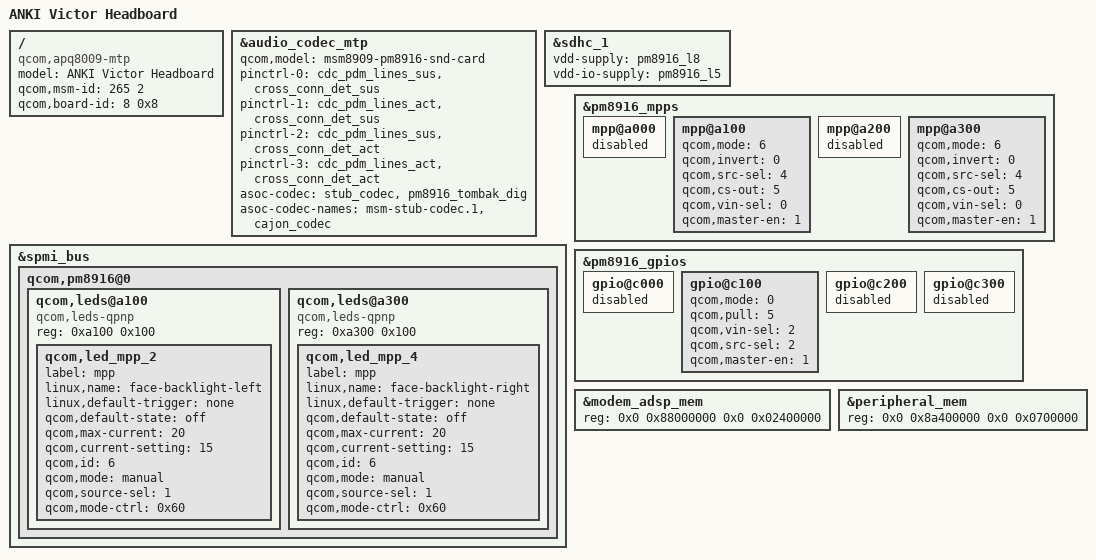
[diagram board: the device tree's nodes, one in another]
/*
 * Copyright (c) 2016, The Linux Foundation. All rights reserved.
 *
 * This program is free software; you can redistribute it and/or modify
 * it under the terms of the GNU General Public License version 2 and
 * only version 2 as published by the Free Software Foundation.
 *
 * This program is distributed in the hope that it will be useful,
 * but WITHOUT ANY WARRANTY; without even the implied warranty of
 * MERCHANTABILITY or FITNESS FOR A PARTICULAR PURPOSE.  See the
 * GNU General Public License for more details.
 */

/dts-v1/;

#include "anki-mtp.dtsi"
#include "msm8909-pm8916.dtsi"
#include "msm8909-pm8916-camera.dtsi"

/ {
	model = "ANKI Victor Headboard";
	compatible = "qcom,apq8009-mtp", "qcom,apq8009", "qcom,mtp";
	qcom,msm-id = <265 2>;
	qcom,board-id= <8 0x8>;   // XXX - this should be our own, right?
};

// The below comes from msm8909-pm8916-mtp - removing disabled hardware

&audio_codec_mtp {
        qcom,model = "msm8909-pm8916-snd-card";
        pinctrl-names =
                "all_off",
                "pri_i2s_act",
                "us_eu_gpio_act",
                "pri_i2s_us_eu_gpio_act";
        pinctrl-0 = <&cdc_pdm_lines_sus &cross_conn_det_sus>;
        pinctrl-1 = <&cdc_pdm_lines_act &cross_conn_det_sus>;
        pinctrl-2 = <&cdc_pdm_lines_sus &cross_conn_det_act>;
        pinctrl-3 = <&cdc_pdm_lines_act &cross_conn_det_act>;
        asoc-codec = <&stub_codec>, <&pm8916_tombak_dig>;
        asoc-codec-names = "msm-stub-codec.1", "cajon_codec";
};

&sdhc_1 {
	vdd-supply = <&pm8916_l8>;
	vdd-io-supply = <&pm8916_l5>;
};

&spmi_bus {
	qcom,pm8916@0 {
		qcom,leds@a100 {
			compatible = "qcom,leds-qpnp";
			reg = <0xa100 0x100>;
			status = "okay";
			qcom,led_mpp_2 {
				label = "mpp";
				linux,name = "face-backlight-left";
				linux,default-trigger = "none";
				qcom,default-state = "off";
				qcom,max-current = <20>;
				qcom,current-setting = <15>;
				qcom,id = <6>;
				qcom,mode = "manual";
				qcom,source-sel = <1>;
				qcom,mode-ctrl = <0x60>;
			};
		};

		qcom,leds@a300 {
			compatible = "qcom,leds-qpnp";
			reg = <0xa300 0x100>;
			status = "okay";
			qcom,led_mpp_4 {
				label = "mpp";
				linux,name = "face-backlight-right";
				linux,default-trigger = "none";
				qcom,default-state = "off";
				qcom,max-current = <20>;
				qcom,current-setting = <15>;
				qcom,id = <6>;
				qcom,mode = "manual";
				qcom,source-sel = <1>;
				qcom,mode-ctrl = <0x60>;
			};
		};
	};
};

&pm8916_mpps {
	mpp@a000 { /* MPP 1 */
		/* VDD_PX */
		status = "disabled";
	};

	mpp@a100 { /* MPP 2 */
		 qcom,mode = <6>;    /* Current sink*/
		 qcom,invert = <0>;    /* Disable invert */
		 qcom,src-sel = <4>;    /* DTEST1 */
		 qcom,cs-out =<5>;
		 qcom,vin-sel = <0>;		/* VPH_PWR */
		 qcom,master-en = <1>;    /* Enable MPP */
	};

	mpp@a200 { /* MPP 3 */
		/* VREF DAC */
		status = "disabled";
	};

	mpp@a300 { /* MPP 4 */
		 qcom,mode = <6>;  /* Current sink*/
		 qcom,invert = <0>;   /* Disable invert */
		 qcom,src-sel = <4>;  /* DTEST1 */
		 qcom,cs-out =<5>;
		 qcom,vin-sel = <0>;		/* VPH_PWR */
		 qcom,master-en = <1>;	/* Enable MPP */
	};
};

&pm8916_gpios {
	gpio@c000 { /* GPIO 1 */
		/* Battery UICC Alarm */
		status = "disabled";
	};

	gpio@c100 { /* GPIO 2 */
		/* NFC_CLK_REQ */
		qcom,mode = <0>; /* QPNP_PIN_MODE_DIG_IN */
		qcom,pull = <5>; /* QPNP_PIN_PULL_NO */
		qcom,vin-sel = <2>; /* QPNP_PIN_VIN2 */
		qcom,src-sel = <2>; /* QPNP_PIN_SEL_FUNC_1 */
		qcom,master-en = <1>;
	};

	gpio@c200 { /* GPIO 3 */
		/* External regulator control for WTR */
		status = "disabled";
	};

	gpio@c300 { /* GPIO 4 */
		/* External regulator control for APC */
		status = "disabled";
	};
};

&modem_adsp_mem {
	reg = <0x0 0x88000000 0x0 0x02400000>;
};

&peripheral_mem {
	reg = <0x0 0x8a400000 0x0 0x0700000>;
};
